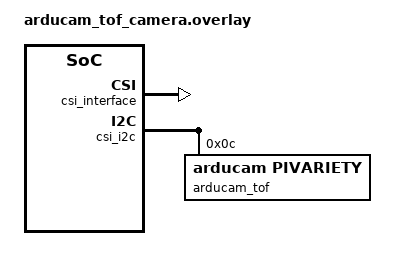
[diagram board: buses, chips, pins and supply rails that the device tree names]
/*
 * Copyright (c) 2026 Richard Osterloh
 * SPDX-License-Identifier: Apache-2.0
 *
 * Arducam ToF depth camera on a Raspberry Pi 15-pin CSI connector.
 *
 * Values are taken from the Raspberry Pi arducam-pivariety-overlay.dts. Note
 * clock-noncontinuous: unlike the IMX219, this module drops its clock lane out
 * of HS between bursts.
 *
 * No link-frequencies here, deliberately. The module reports
 * VIDEO_CID_PIXEL_RATE (50 MHz) and the driver registers it, so
 * video_get_csi_link_freq() derives the link frequency itself:
 *
 *   link_freq = pixel_rate * bits_per_pixel / (2 * lanes)
 *             = 50000000 * 12 / (2 * 2) = 150000000 Hz, i.e. 300 Mbps/lane
 *
 * which is the same expression, and the same answer, as the Raspberry Pi
 * kernel's v4l2_get_link_freq_ctrl() - verified against it, where the CFE logs
 * "Using a link rate of 300 Mbps" while capturing 240x180 Y12P from this
 * module.
 *
 * This property previously carried 493500000, copied from the IMX219 shield
 * rather than from anything this module reports. That is 987 Mbps/lane, 3.3x
 * the real rate, and it put the ESP32-P4 D-PHY in the 950-1000 Mbps band for a
 * transmitter running at 300 - a link that carries no packets and latches no
 * errors anywhere. Prefer no value over a guessed one.
 */

#include <zephyr/dt-bindings/video/video-interfaces.h>

/ {
	chosen {
		zephyr,camera = &csi_capture_port;
	};
};

&csi_interface {
	status = "okay";
};

&csi_ep_in {
	remote-endpoint-label = "arducam_tof_ep_out";
	bus-type = <VIDEO_BUS_TYPE_CSI2_DPHY>;
	data-lanes = <1 2>;
};

&csi_i2c {
	arducam_tof: arducam_pivariety@c {
		compatible = "arducam,pivariety";
		reg = <0x0c>;

		port {
			arducam_tof_ep_out: endpoint {
				remote-endpoint-label = "csi_ep_in";
				bus-type = <VIDEO_BUS_TYPE_CSI2_DPHY>;
				data-lanes = <1 2>;
			};
		};
	};
};
